# MKL05Z4 register map
Vendor: Freescale Semiconductor, Inc.; Series: Kinetis_L; File version: 1.6
CPU: CM0PLUS r0p0, little endian, no MPU, no FPU, VTOR, 2 interrupt priority bits
Registers are 32-bit, read-write, reset 0x0 unless marked. A register's access mark holds for its fields unless they carry their own. Offsets are from the block's base; [hi:lo] are bit positions; {n}, {i} and the like mark numbered series; 'fields as' and 'values as' point back to an identical list.

## TSI0 — Touch sense input
Base 0x40045000; register names take the prefix TSI0_
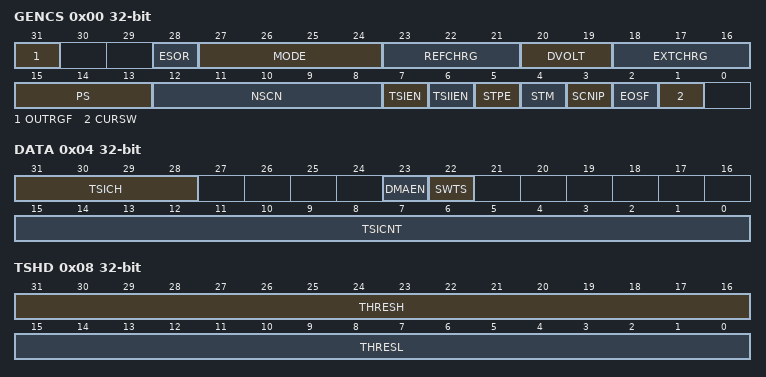
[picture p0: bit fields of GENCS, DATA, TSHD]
0x00 GENCS — TSI General Control and Status Register
  [31] OUTRGF — Out of Range Flag.
  [28] ESOR — End-of-scan or Out-of-Range Interrupt Selection
    0=Out-of-range interrupt is allowed; 1=End-of-scan interrupt is allowed
  [27:24] MODE — TSI analog modes setup and status bits.
    0=Set TSI in capacitive sensing(non-noise detection) mode; 4=Set TSI analog to work in single threshold noise detection mode and the frequency limitation circuit is disabled; 8=Set TSI analog to work in single threshold noise detection mode and the frequency limitation circuit is enabled to work in higher frequencies operations; 12=Set TSI analog to work in automatic noise detection mode
  [23:21] REFCHRG
    0=500 nA; 1=1 uA; 2=2 uA; 3=4 uA; 4=8 uA; 5=16 uA; 6=32 uA; 7=64 uA
  [20:19] DVOLT
    0=DV = 1.03 V; VP = 1.33 V; Vm = 0.30 V; 1=DV = 0.73 V; VP = 1.18 V; Vm = 0.45 V; 2=DV = 0.43 V; VP = 1.03 V; Vm = 0.60 V; 3=DV = 0.29 V; VP = 0.95 V; Vm = 0.67 V
  [18:16] EXTCHRG
    values as REFCHRG
  [15:13] PS
    0=Electrode Oscillator Frequency divided by 1; 1=Electrode Oscillator Frequency divided by 2; 2=Electrode Oscillator Frequency divided by 4; 3=Electrode Oscillator Frequency divided by 8; 4=Electrode Oscillator Frequency divided by 16; 5=Electrode Oscillator Frequency divided by 32; 6=Electrode Oscillator Frequency divided by 64; 7=Electrode Oscillator Frequency divided by 128
  [12:8] NSCN
    0=Once per electrode; 1=Twice per electrode; {v}={v+1} times per electrode (v=2..31)
  [7] TSIEN — Touch Sensing Input Module Enable
    0=TSI module disabled; 1=TSI module enabled
  [6] TSIIEN — Touch Sensing Input Interrupt Enable
    0=TSI interrupt is disabled; 1=TSI interrupt is enabled
  [5] STPE — TSI STOP Enable
    0=TSI is disabled when MCU goes into low power mode; 1=Allows TSI to continue running in all low power modes
  [4] STM — Scan Trigger Mode
    0=Software trigger scan; 1=Hardware trigger scan
  [3] SCNIP ro — Scan In Progress Status
    0=No scan in progress; 1=Scan in progress
  [2] EOSF — End of Scan Flag
    0=Scan not complete; 1=Scan complete
  [1] CURSW
    0=The current source pair are not swapped; 1=The current source pair are swapped
0x04 DATA — TSI DATA Register
  [31:28] TSICH
    {v}=Channel {v} (v=0..15)
  [23] DMAEN — DMA Transfer Enabled
    0=Interrupt is selected when the interrupt enable bit is set and the corresponding TSI events assert; 1=DMA transfer request is selected when the interrupt enable bit is set and the corresponding TSI events assert
  [22] SWTS wo — Software Trigger Start
    0=No effect; 1=Start a scan to determine which channel is specified by TSI_DATA[TSICH]
  [15:0] TSICNT ro — TSI Conversion Counter Value
0x08 TSHD — TSI Threshold Register
  [31:16] THRESH — TSI Wakeup Channel High-threshold
  [15:0] THRESL — TSI Wakeup Channel Low-threshold

## PORTA — Pin Control and Interrupts
Base 0x40049000; register names take the prefix PORTA_
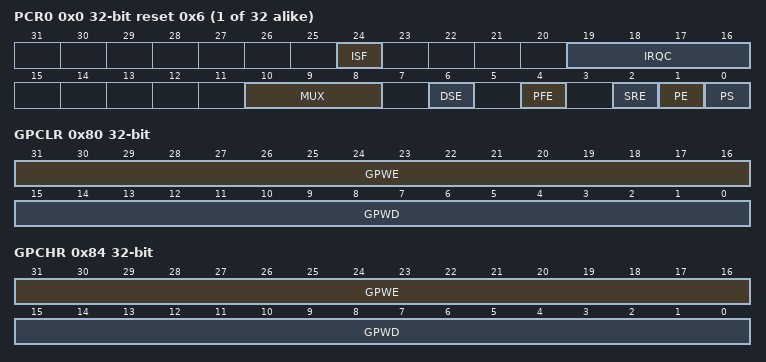
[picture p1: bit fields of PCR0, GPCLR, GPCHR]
{0x0+4i} PCR{i} (i=0..31) reset 0x6 — Pin Control Register n
  [24] ISF — Interrupt Status Flag
    0=Configured interrupt is not detected; 1=Configured interrupt is detected. If the pin is configured to generate a DMA request, then the corresponding flag will be cleared automatically at the completion of the requested DMA transfer. Otherwise, the flag remains set until a logic one is written to the flag. If the pin is configured for a level sensitive interrupt and the pin remains asserted, then the flag is set again immediately after it is cleared.
  [19:16] IRQC — Interrupt Configuration
    0=Interrupt/DMA request disabled; 1=DMA request on rising edge; 2=DMA request on falling edge; 3=DMA request on either edge; 8=Interrupt when logic zero; 9=Interrupt on rising edge; 10=Interrupt on falling edge; 11=Interrupt on either edge; 12=Interrupt when logic one
  [10:8] MUX — Pin Mux Control
    0=Pin disabled (analog); 1=Alternative 1 (GPIO); {v}=Alternative {v} (chip-specific) (v=2..7)
  [6] DSE — Drive Strength Enable
    0=Low drive strength is configured on the corresponding pin, if pin is configured as a digital output; 1=High drive strength is configured on the corresponding pin, if pin is configured as a digital output
  [4] PFE — Passive Filter Enable
    0=Passive input filter is disabled on the corresponding pin; 1=Passive input filter is enabled on the corresponding pin, if the pin is configured as a digital input. Refer to the device data sheet for filter characteristics.
  [2] SRE — Slew Rate Enable
    0=Fast slew rate is configured on the corresponding pin, if the pin is configured as a digital output; 1=Slow slew rate is configured on the corresponding pin, if the pin is configured as a digital output
  [1] PE — Pull Enable
    0=Internal pullup or pulldown resistor is not enabled on the corresponding pin; 1=Internal pullup or pulldown resistor is enabled on the corresponding pin, if the pin is configured as a digital input
  [0] PS — Pull Select
    0=Internal pulldown resistor is enabled on the corresponding pin, if the corresponding Port Pull Enable field is set; 1=Internal pullup resistor is enabled on the corresponding pin, if the corresponding Port Pull Enable field is set
0x80 GPCLR wo — Global Pin Control Low Register
  [31:16] GPWE — Global Pin Write Enable
    0=Corresponding Pin Control Register is not updated with the value in GPWD; 1=Corresponding Pin Control Register is updated with the value in GPWD
  [15:0] GPWD — Global Pin Write Data
0x84 GPCHR wo — Global Pin Control High Register
  fields as GPCLR
0xA0 ISFR — Interrupt Status Flag Register
  [31:0] ISF — Interrupt Status Flag
    values as PCR0.ISF

## Notices in the file
Redistribution and use in source and binary forms, with or without modification,
are permitted provided that the following conditions are met:
o Redistributions of source code must retain the above copyright notice, this list
of conditions and the following disclaimer.
o Redistributions in binary form must reproduce the above copyright notice, this
list of conditions and the following disclaimer in the documentation and/or
other materials provided with the distribution.
o Neither the name of Freescale Semiconductor, Inc. nor the names of its
contributors may be used to endorse or promote products derived from this
software without specific prior written permission.
THIS SOFTWARE IS PROVIDED BY THE COPYRIGHT HOLDERS AND CONTRIBUTORS "AS IS" AND
ANY EXPRESS OR IMPLIED WARRANTIES, INCLUDING, BUT NOT LIMITED TO, THE IMPLIED
WARRANTIES OF MERCHANTABILITY AND FITNESS FOR A PARTICULAR PURPOSE ARE
DISCLAIMED. IN NO EVENT SHALL THE COPYRIGHT HOLDER OR CONTRIBUTORS BE LIABLE FOR
ANY DIRECT, INDIRECT, INCIDENTAL, SPECIAL, EXEMPLARY, OR CONSEQUENTIAL DAMAGES
(INCLUDING, BUT NOT LIMITED TO, PROCUREMENT OF SUBSTITUTE GOODS OR SERVICES;
LOSS OF USE, DATA, OR PROFITS; OR BUSINESS INTERRUPTION) HOWEVER CAUSED AND ON
ANY THEORY OF LIABILITY, WHETHER IN CONTRACT, STRICT LIABILITY, OR TORT
(INCLUDING NEGLIGENCE OR OTHERWISE) ARISING IN ANY WAY OUT OF THE USE OF THIS
SOFTWARE, EVEN IF ADVISED OF THE POSSIBILITY OF SUCH DAMAGE.
